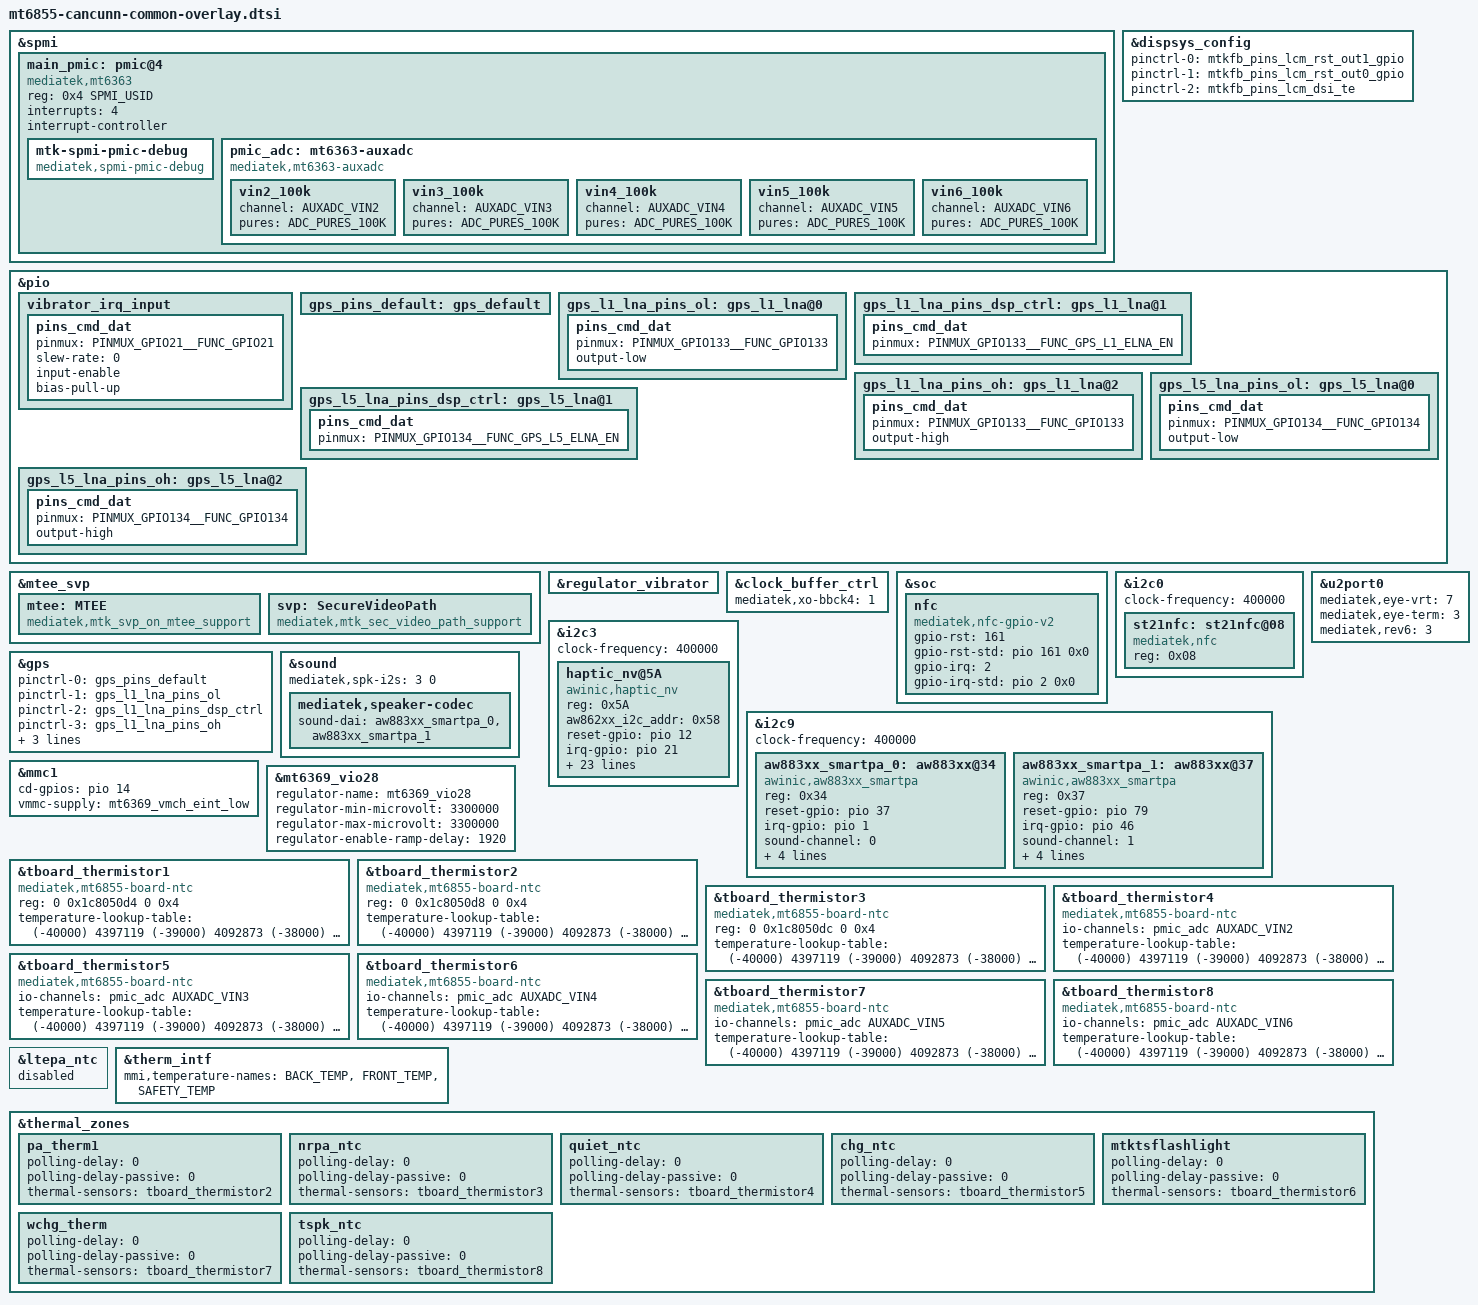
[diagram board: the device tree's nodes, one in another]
/* Copyright (c) 2020, The Linux Foundation. All rights reserved.
 *
 * This program is free software; you can redistribute it and/or modify
 * it under the terms of the GNU General Public License version 2 and
 * only version 2 as published by the Free Software Foundation.
 *
 * This program is distributed in the hope that it will be useful,
 * but WITHOUT ANY WARRANTY; without even the implied warranty of
 * MERCHANTABILITY or FITNESS FOR A PARTICULAR PURPOSE.  See the
 * GNU General Public License for more details.
 */

#include "mediatek/mt6855-moto-common-overlay.dtsi"
#include <dt-bindings/gpio/gpio.h>
#include "mediatek/cancunn-display.dtsi"
#include "mediatek/cancunn-charger.dtsi"
#include "mediatek/mt6855_cancunn_camera_overlay.dtsi"
#include "mediatek/cancunn-fps.dtsi"
#include "mediatek/cancunn-sar.dtsi"
#include "mediatek/mt6855-moto-memory.dtsi"

//#include "mediatek/mt6363.dtsi"
#include <dt-bindings/iio/mt635x-auxadc.h>
#include <dt-bindings/spmi/spmi.h>

&spmi {
	main_pmic: pmic@4 {
		compatible = "mediatek,mt6363";
		reg = <0x4 SPMI_USID>;
		interrupts = <4>;
		#address-cells = <1>;
		#size-cells = <0>;
		interrupt-controller;
		#interrupt-cells = <2>;

		mtk-spmi-pmic-debug {
			compatible = "mediatek,spmi-pmic-debug";
		};

		pmic_adc: mt6363-auxadc {
			compatible = "mediatek,mt6363-auxadc";
			#io-channel-cells = <1>;
			vin2_100k {
				channel = <AUXADC_VIN2>;
				pures = <ADC_PURES_100K>;
			};
			vin3_100k {
				channel = <AUXADC_VIN3>;
				pures = <ADC_PURES_100K>;
			};
			vin4_100k {
				channel = <AUXADC_VIN4>;
				pures = <ADC_PURES_100K>;
			};
			vin5_100k {
				channel = <AUXADC_VIN5>;
				pures = <ADC_PURES_100K>;
			};
                        vin6_100k {
				channel = <AUXADC_VIN6>;
				pures = <ADC_PURES_100K>;
			};
		};

	};
};

&dispsys_config {
	pinctrl-names =
		"lcm_rst_out1_gpio", "lcm_rst_out0_gpio",
		"mode_te_te";
	pinctrl-0 = <&mtkfb_pins_lcm_rst_out1_gpio>;
	pinctrl-1 = <&mtkfb_pins_lcm_rst_out0_gpio>;
	pinctrl-2 = <&mtkfb_pins_lcm_dsi_te>;
	status = "okay";
};

&pio {
	vibrator_irq_input: vibrator_irq_input {
		pins_cmd_dat {
			pinmux = <PINMUX_GPIO21__FUNC_GPIO21>;
			slew-rate = <0>;
			input-enable;
			bias-pull-up;
		};
	};

/*
	fingerfp_rst_high: fingerfp_rst_high {
		pins_cmd_dat {
			pinmux = <PINMUX_GPIO157__FUNC_GPIO157>;
			slew-rate = <1>;
			output-high;
		};
	};

	fingerfp_rst_low: fingerfp_rst_low {
		pins_cmd_dat {
			pinmux = <PINMUX_GPIO157__FUNC_GPIO157>;
			slew-rate = <1>;
			output-low;
		};
	};

	fingerfp_irq_active: fingerfp_irq_active {
		pins_cmd_dat {
			pinmux = <PINMUX_GPIO15__FUNC_GPIO15>;
			slew-rate = <0>;
			bias-disable;
		};
	};

	fingerfp_spi_active: fingerfp_spi_active {
		pins_cmd_dat {
			pinmux = <PINMUX_GPIO68__FUNC_SPI1_MI>, <PINMUX_GPIO66__FUNC_SPI1_CSB>, <PINMUX_GPIO67__FUNC_SPI1_MO>, <PINMUX_GPIO65__FUNC_SPI1_CLK>;
			drive-strength = <2>;
		};
	};

	fingerfp_spi_default: fingerfp_spi_default {
		pins_cmd_dat {
			pinmux = <PINMUX_GPIO68__FUNC_SPI1_MI>, <PINMUX_GPIO66__FUNC_SPI1_CSB>, <PINMUX_GPIO67__FUNC_SPI1_MO>, <PINMUX_GPIO65__FUNC_SPI1_CLK>;
			drive-strength = <2>;
		};
	};
	fps_irq: fps_irq {
		pins_cmd_dat {
			pinmux = <PINMUX_GPIO15__FUNC_GPIO15>;
			slew-rate = <0>;
			bias-disable;
		};
	};

	fps_reset_high: fps_reset_high {
		pins_cmd_dat {
			pinmux = <PINMUX_GPIO157__FUNC_GPIO157>;
			slew-rate = <1>;
			output-high;
		};
	};

	fps_reset_low: fps_reset_low {
		pins_cmd_dat {
			pinmux = <PINMUX_GPIO157__FUNC_GPIO157>;
			slew-rate = <1>;
			output-low;
		};
	};
*/
};

/* FINGERPRINT start */


/* SVP */
&mtee_svp {
	mtee: MTEE {
		compatible = "mediatek,mtk_svp_on_mtee_support";
	};
	svp: SecureVideoPath {
		compatible = "mediatek,mtk_sec_video_path_support";
	};
};

/*
&spi1 {
	status = "okay";
	mediatek,pad-select = <0>, <1>;
	tee-only;

	fingerprint@0 {
		compatible = "mediatek,fingerprint";
		reg = <0>;
		spi-max-frequency = <8000000>;
		status = "okay";
	};
	fpc_tee@1 {
		compatible = "fpc,fpc_spi";
		reg = <1>;
		fpc,enable-wakeup;
		spi-max-frequency = <8000000>;
		netlink-event = <31>;
		status = "okay";
	};
};

&odm {
	fp_egistec {
		compatible = "fp-egistec";
		interrupt-parent = <&pio>;
		interrupts = <15 IRQ_TYPE_EDGE_RISING 15 0>;

		egistec,gpio_reset = <&pio 157 0x0>;
		egistec,gpio_irq = <&pio 15 0x0>;
		fp-ctrl-power;
		vcc_fp-supply = <&mt6369_vfp>;	// ldo for support module vcc
		egis-fp,vcc-voltage = <3300000 3300000>;	// ldo voltage default 3.3V
		egis-fp,vcc-current = <100000>;
		pinctrl-names = "egis_rst_high", "egis_rst_low", "egis_irq_active", "egis_spi_active", "egis_spi_default";
		pinctrl-0 = <&fingerfp_rst_high>;
		pinctrl-1 = <&fingerfp_rst_low>;
		pinctrl-2 = <&fingerfp_irq_active>;
		pinctrl-3 = <&fingerfp_spi_active>;
		pinctrl-4 = <&fingerfp_spi_default>;

		status="okay";
	};

	fingerprint_int: fingerprint_int {
		compatible = "mediatek,fingerprint-fpc";
		fpc,enable-wakeup;
		interrupt-parent = <&pio>;
		interrupts = <15 IRQ_TYPE_EDGE_RISING 15 0>;
		rgltr-ctrl-support;
		fp,vdd-supply = <&mt6369_vfp>;
		fp,voltage-range = <3300000 3300000>;
		fp,vdd-current = <100000>;
		pinctrl-names = "fingerprint_irq", "fingerprint_reset_high", "fingerprint_reset_low";
		pinctrl-0 = <&fps_irq>;
		pinctrl-1 = <&fps_reset_high>;
		pinctrl-2 = <&fps_reset_low>;
		fpc,rst= <&pio 157 0>;
		fpc,irq = <&pio 15 0>;
		status = "okay";
	};
};
*/

&regulator_vibrator {
	status = "ok";
};


&clock_buffer_ctrl {
	mediatek,xo-bbck4 = <1>;
};

&soc {
      nfc {
        compatible = "mediatek,nfc-gpio-v2";
        gpio-rst = <161>;
        gpio-rst-std = <&pio 161 0x0>;
        gpio-irq = <2>;
        gpio-irq-std = <&pio 2 0x0>;
        status = "okay";
      };
};


&i2c0 {
        status = "okay";
        clock-frequency = <400000>;
	st21nfc: st21nfc@08 {
		compatible = "mediatek,nfc";
		reg = <0x08>;
		//interrupt-parent = <&pio>;
		//interrupts = <2 0>;
		//reset-gpio = <&pio 161 0x00>;
		//irq-gpio = <&pio 2 0x00>;
		//clkreq-gpios = <&pio 160 0x00>;
		status = "ok";
	};
};

&i2c3 {
	clock-frequency = <400000>;
	haptic_nv@5A{
		compatible = "awinic,haptic_nv";
		reg = < 0x5A >;
		aw862xx_i2c_addr = < 0x58 >;
		reset-gpio = <&pio 12 0>;
		irq-gpio = <&pio 21 0>;
		pinctrl-names = "irq_active";
		pinctrl-0 = <&vibrator_irq_input>;
		aw8622x_vib_lk_f0_cali = < 0 >;
		aw8622x_vib_mode = < 0 >; /* mode: RAM mode->0; CONT mode->1 */
		aw8622x_vib_f0_pre = < 2050 >;
		aw8622x_vib_f0_cali_percen = < 7 >;
		aw8622x_vib_cont_drv1_lvl = < 0x7F >;
		aw8622x_vib_cont_drv2_lvl = < 0x38 >;
		aw8622x_vib_cont_brk_time = < 0x08 >;
		aw8622x_vib_cont_tset = < 0x06 >;
		aw8622x_vib_cont_bemf_set = < 0x02 >;
		aw8622x_vib_cont_drv_width = < 0x56 >;
		aw8622x_vib_cont_wait_num = < 0x06 >;
		aw8622x_vib_cont_brk_gain = < 0x0A >;
		aw8622x_vib_cont_drv1_time = < 0x08 >;
		aw8622x_vib_cont_drv2_time = < 0x14 >;
		aw8622x_vib_cont_track_margin = < 0x0F >;
		aw8622x_vib_sine_array = < 0x05 0xB2 0xFF 0xEF >; /* SIN_H SIN_L COS_H COS_L*/
		aw8622x_vib_d2s_gain = < 0x05 >;
		aw8622x_vib_prctmode = < 0x2D 0x3E 0x3F >;
		aw8622x_vib_trig_config = < 0 0 0 1 0 2 0
					0 0 0 1 0 2 0
					0 0 0 1 0 2 0 >;
		aw8622x_vib_duration_time = < 34 67 100 >;
		aw8622x_vib_is_enabled_auto_brk;
		status = "okay";
	};
};

/* GPS GPIO standardization start */
&pio {
	gps_pins_default: gps_default {
	};
	gps_l1_lna_pins_ol: gps_l1_lna@0 {
		pins_cmd_dat {
			pinmux = <PINMUX_GPIO133__FUNC_GPIO133>;
			output-low;
		};
	};
	gps_l1_lna_pins_dsp_ctrl: gps_l1_lna@1 {
		pins_cmd_dat {
			pinmux = <PINMUX_GPIO133__FUNC_GPS_L1_ELNA_EN>;
		};
	};
	gps_l1_lna_pins_oh: gps_l1_lna@2 {
		pins_cmd_dat {
			pinmux = <PINMUX_GPIO133__FUNC_GPIO133>;
			output-high;
		};
	};
	gps_l5_lna_pins_ol: gps_l5_lna@0 {
		pins_cmd_dat {
			pinmux = <PINMUX_GPIO134__FUNC_GPIO134>;
			output-low;
		};
	};
	gps_l5_lna_pins_dsp_ctrl: gps_l5_lna@1 {
		pins_cmd_dat {
			pinmux = <PINMUX_GPIO134__FUNC_GPS_L5_ELNA_EN>;
		};
	};
	gps_l5_lna_pins_oh: gps_l5_lna@2 {
		pins_cmd_dat {
			pinmux = <PINMUX_GPIO134__FUNC_GPIO134>;
			output-high;
		};
	};
};



&gps {
	pinctrl-names = "default",
		"gps_l1_lna_disable",
		"gps_l1_lna_dsp_ctrl",
		"gps_l1_lna_enable",
		"gps_l5_lna_disable",
		"gps_l5_lna_dsp_ctrl",
		"gps_l5_lna_enable";
	pinctrl-0 = <&gps_pins_default>;
	pinctrl-1 = <&gps_l1_lna_pins_ol>;
	pinctrl-2 = <&gps_l1_lna_pins_dsp_ctrl>;
	pinctrl-3 = <&gps_l1_lna_pins_oh>;
	pinctrl-4 = <&gps_l5_lna_pins_ol>;
	pinctrl-5 = <&gps_l5_lna_pins_dsp_ctrl>;
	pinctrl-6 = <&gps_l5_lna_pins_oh>;
	status = "okay";
};
/* GPS GPIO standardization end */

//#include "mediatek/cust_mt6855_touch_1080x2400.dtsi"
#include "mediatek/cust_mt6855_camera_v4l2.dtsi"
/delete-node/ &camera_main_two_af_mtk;

&i2c9 {
	status = "okay";
	clock-frequency = <400000>;
	#address-cells = <1>;
	#size-cells = <0>;

	aw883xx_smartpa_0: aw883xx@34 {
                compatible = "awinic,aw883xx_smartpa";
                #sound-dai-cells = <0>;
                reg = <0x34>;
                reset-gpio = <&pio 37 0>;
                irq-gpio = <&pio 1 0>;
                sound-channel = <0>;
                re-min = <1000>;
                re-max = <40000>;
		rename-flag=<1>;
		fade-enable = <1>;
                status = "okay";
        };
        aw883xx_smartpa_1: aw883xx@37 {
                compatible = "awinic,aw883xx_smartpa";
                #sound-dai-cells = <0>;
                reg = <0x37>;
                reset-gpio = <&pio 79 0>;
                irq-gpio = <&pio 46 0>;
                sound-channel = <1>;
                re-min = <1000>;
                re-max = <40000>;
		rename-flag=<1>;
		fade-enable = <1>;
                status = "okay";
        };
};

&sound {
	mediatek,spk-i2s = <3 0>;
	mediatek,speaker-codec {
		sound-dai = <&aw883xx_smartpa_0 &aw883xx_smartpa_1>;
	};
};

&mmc1 {
	cd-gpios = <&pio 14 GPIO_ACTIVE_HIGH>;
	vmmc-supply = <&mt6369_vmch_eint_low>;
};
#include "cancunn-touch.dtsi"

//for alsps sensor tmd2755x
&mt6369_vio28 {
	regulator-name = "mt6369_vio28";
	regulator-min-microvolt = <3300000>;
	regulator-max-microvolt = <3300000>;
	regulator-enable-ramp-delay = <1920>;
};

&u2port0{
	mediatek,eye-vrt = <7>;
	mediatek,eye-term = <3>;
	mediatek,rev6 = <3>;
};


//#include <k6855v1_64/cust.dtsi>
/*End of this file, DO NOT ADD ANYTHING HERE*/

&tboard_thermistor1 {
	compatible = "mediatek,mt6855-board-ntc";
	status = "okay";
	#thermal-sensor-cells = <0>;
	reg = <0 0x1c8050d4 0 0x4>; /* TIA DATA T0 */
	temperature-lookup-table = <
		(-40000) 4397119
		(-39000) 4092873
		(-38000) 3811717
		(-37000) 3551748
		(-36000) 3311235
		(-35000) 3088598
		(-34000) 2882395
		(-33000) 2691309
		(-32000) 2514137
		(-31000) 2349777
		(-30000) 2197225
		(-29000) 2055557
		(-28000) 1923931
		(-27000) 1801573
		(-26000) 1687773
		(-25000) 1581880
		(-24000) 1483099
		(-23000) 1391113
		(-22000) 1305412
		(-21000) 1225530
		(-20000) 1151036
		(-19000) 1081535
		(-18000) 1016661
		(-17000) 956079
		(-16000) 899480
		(-15000) 846578
		(-14000) 797111
		(-13000) 750834
		(-12000) 707523
		(-11000) 666972
		(-10000) 628988
		(-9000) 593342
		(-8000) 559930
		(-7000) 528601
		(-6000) 499212
		(-5000) 471632
		(-4000) 445771
		(-3000) 421479
		(-2000) 398652
		(-1000) 377192
		0 357011
		1000 338005
		2000 320121
		3000 303286
		4000 287433
		5000 272499
		6000 258426
		7000 245160
		8000 232649
		9000 220847
		10000 209710
		11000 199196
		12000 189268
		13000 179890
		14000 171027
		15000 162651
		16000 154726
		17000 147232
		18000 140142
		19000 133432
		20000 127080
		21000 121066
		22000 115368
		23000 109970
		24000 104852
		25000 100000
		26000 95398
		27000 91032
		28000 86889
		29000 82956
		30000 79222
		31000 75675
		32000 72306
		33000 69104
		34000 66061
		35000 63167
		36000 60415
		37000 57797
		38000 55306
		39000 52934
		40000 50677
		41000 48528
		42000 46482
		43000 44533
		44000 42675
		45000 40904
		46000 39213
		47000 37601
		48000 36063
		49000 34595
		50000 33195
		51000 31859
		52000 30584
		53000 29366
		54000 28203
		55000 27091
		56000 26028
		57000 25013
		58000 24042
		59000 23113
		60000 22224
		61000 21374
		62000 20560
		63000 19782
		64000 19036
		65000 18322
		66000 17640
		67000 16986
		68000 16360
		69000 15759
		70000 15184
		71000 14631
		72000 14100
		73000 13591
		74000 13103
		75000 12635
		76000 12187
		77000 11756
		78000 11343
		79000 10946
		80000 10565
		81000 10199
		82000 9847
		83000 9509
		84000 9184
		85000 8872
		86000 8572
		87000 8283
		88000 8005
		89000 7738
		90000 7481
		91000 7234
		92000 6997
		93000 6769
		94000 6548
		95000 6337
		96000 6132
		97000 5934
		98000 5744
		99000 5561
		100000 5384
		101000 5214
		102000 5051
		103000 4893
		104000 4741
		105000 4594
		106000 4453
		107000 4316
		108000 4184
		109000 4057
		110000 3934
		111000 3816
		112000 3701
		113000 3591
		114000 3484
		115000 3380
		116000 3281
		117000 3185
		118000 3093
		119000 3003
		120000 2916
		121000 2832
		122000 2751
		123000 2672
		124000 2596
		125000 2522>;
};

&tboard_thermistor2 {
	compatible = "mediatek,mt6855-board-ntc";
	status = "okay";
	#thermal-sensor-cells = <0>;
	reg = <0 0x1c8050d8 0 0x4>; /* TIA DATA T1 */
	temperature-lookup-table = <
		(-40000) 4397119
		(-39000) 4092873
		(-38000) 3811717
		(-37000) 3551748
		(-36000) 3311235
		(-35000) 3088598
		(-34000) 2882395
		(-33000) 2691309
		(-32000) 2514137
		(-31000) 2349777
		(-30000) 2197225
		(-29000) 2055557
		(-28000) 1923931
		(-27000) 1801573
		(-26000) 1687773
		(-25000) 1581880
		(-24000) 1483099
		(-23000) 1391113
		(-22000) 1305412
		(-21000) 1225530
		(-20000) 1151036
		(-19000) 1081535
		(-18000) 1016661
		(-17000) 956079
		(-16000) 899480
		(-15000) 846578
		(-14000) 797111
		(-13000) 750834
		(-12000) 707523
		(-11000) 666972
		(-10000) 628988
		(-9000) 593342
		(-8000) 559930
		(-7000) 528601
		(-6000) 499212
		(-5000) 471632
		(-4000) 445771
		(-3000) 421479
		(-2000) 398652
		(-1000) 377192
		0 357011
		1000 338005
		2000 320121
		3000 303286
		4000 287433
		5000 272499
		6000 258426
		7000 245160
		8000 232649
		9000 220847
		10000 209710
		11000 199196
		12000 189268
		13000 179890
		14000 171027
		15000 162651
		16000 154726
		17000 147232
		18000 140142
		19000 133432
		20000 127080
		21000 121066
		22000 115368
		23000 109970
		24000 104852
		25000 100000
		26000 95398
		27000 91032
		28000 86889
		29000 82956
		30000 79222
		31000 75675
		32000 72306
		33000 69104
		34000 66061
		35000 63167
		36000 60415
		37000 57797
		38000 55306
		39000 52934
		40000 50677
		41000 48528
		42000 46482
		43000 44533
		44000 42675
		45000 40904
		46000 39213
		47000 37601
		48000 36063
		49000 34595
		50000 33195
		51000 31859
		52000 30584
		53000 29366
		54000 28203
		55000 27091
		56000 26028
		57000 25013
		58000 24042
		59000 23113
		60000 22224
		61000 21374
		62000 20560
		63000 19782
		64000 19036
		65000 18322
		66000 17640
		67000 16986
		68000 16360
		69000 15759
		70000 15184
		71000 14631
		72000 14100
		73000 13591
		74000 13103
		75000 12635
		76000 12187
		77000 11756
		78000 11343
		79000 10946
		80000 10565
		81000 10199
		82000 9847
		83000 9509
		84000 9184
		85000 8872
		86000 8572
		87000 8283
		88000 8005
		89000 7738
		90000 7481
		91000 7234
		92000 6997
		93000 6769
		94000 6548
		95000 6337
		96000 6132
		97000 5934
		98000 5744
		99000 5561
		100000 5384
		101000 5214
		102000 5051
		103000 4893
		104000 4741
		105000 4594
		106000 4453
		107000 4316
		108000 4184
		109000 4057
		110000 3934
		111000 3816
		112000 3701
		113000 3591
		114000 3484
		115000 3380
		116000 3281
		117000 3185
		118000 3093
		119000 3003
		120000 2916
		121000 2832
		122000 2751
		123000 2672
		124000 2596
		125000 2522>;
};

&tboard_thermistor3 {
	compatible = "mediatek,mt6855-board-ntc";
	status = "okay";
	#thermal-sensor-cells = <0>;
	reg = <0 0x1c8050dc 0 0x4>; /* TIA DATA T2 */
	temperature-lookup-table = <
		(-40000) 4397119
		(-39000) 4092873
		(-38000) 3811717
		(-37000) 3551748
		(-36000) 3311235
		(-35000) 3088598
		(-34000) 2882395
		(-33000) 2691309
		(-32000) 2514137
		(-31000) 2349777
		(-30000) 2197225
		(-29000) 2055557
		(-28000) 1923931
		(-27000) 1801573
		(-26000) 1687773
		(-25000) 1581880
		(-24000) 1483099
		(-23000) 1391113
		(-22000) 1305412
		(-21000) 1225530
		(-20000) 1151036
		(-19000) 1081535
		(-18000) 1016661
		(-17000) 956079
		(-16000) 899480
		(-15000) 846578
		(-14000) 797111
		(-13000) 750834
		(-12000) 707523
		(-11000) 666972
		(-10000) 628988
		(-9000) 593342
		(-8000) 559930
		(-7000) 528601
		(-6000) 499212
		(-5000) 471632
		(-4000) 445771
		(-3000) 421479
		(-2000) 398652
		(-1000) 377192
		0 357011
		1000 338005
		2000 320121
		3000 303286
		4000 287433
		5000 272499
		6000 258426
		7000 245160
		8000 232649
		9000 220847
		10000 209710
		11000 199196
		12000 189268
		13000 179890
		14000 171027
		15000 162651
		16000 154726
		17000 147232
		18000 140142
		19000 133432
		20000 127080
		21000 121066
		22000 115368
		23000 109970
		24000 104852
		25000 100000
		26000 95398
		27000 91032
		28000 86889
		29000 82956
		30000 79222
		31000 75675
		32000 72306
		33000 69104
		34000 66061
		35000 63167
		36000 60415
		37000 57797
		38000 55306
		39000 52934
		40000 50677
		41000 48528
		42000 46482
		43000 44533
		44000 42675
		45000 40904
		46000 39213
		47000 37601
		48000 36063
		49000 34595
		50000 33195
		51000 31859
		52000 30584
		53000 29366
		54000 28203
		55000 27091
		56000 26028
		57000 25013
		58000 24042
		59000 23113
		60000 22224
		61000 21374
		62000 20560
		63000 19782
		64000 19036
		65000 18322
		66000 17640
		67000 16986
		68000 16360
		69000 15759
		70000 15184
		71000 14631
		72000 14100
		73000 13591
		74000 13103
		75000 12635
		76000 12187
		77000 11756
		78000 11343
		79000 10946
		80000 10565
		81000 10199
		82000 9847
		83000 9509
		84000 9184
		85000 8872
		86000 8572
		87000 8283
		88000 8005
		89000 7738
		90000 7481
		91000 7234
		92000 6997
		93000 6769
		94000 6548
		95000 6337
		96000 6132
		97000 5934
		98000 5744
		99000 5561
		100000 5384
		101000 5214
		102000 5051
		103000 4893
		104000 4741
		105000 4594
		106000 4453
		107000 4316
		108000 4184
		109000 4057
		110000 3934
		111000 3816
		112000 3701
		113000 3591
		114000 3484
		115000 3380
		116000 3281
		117000 3185
		118000 3093
		119000 3003
		120000 2916
		121000 2832
		122000 2751
		123000 2672
		124000 2596
		125000 2522>;
};

&tboard_thermistor4 {
	compatible = "mediatek,mt6855-board-ntc";
	status = "okay";
	#thermal-sensor-cells = <0>;
	io-channels = <&pmic_adc AUXADC_VIN2>;
	io-channel-names = "QUIET_NTC";
	temperature-lookup-table = <
		(-40000) 4397119
		(-39000) 4092873
		(-38000) 3811717
		(-37000) 3551748
		(-36000) 3311235
		(-35000) 3088598
		(-34000) 2882395
		(-33000) 2691309
		(-32000) 2514137
		(-31000) 2349777
		(-30000) 2197225
		(-29000) 2055557
		(-28000) 1923931
		(-27000) 1801573
		(-26000) 1687773
		(-25000) 1581880
		(-24000) 1483099
		(-23000) 1391113
		(-22000) 1305412
		(-21000) 1225530
		(-20000) 1151036
		(-19000) 1081535
		(-18000) 1016661
		(-17000) 956079
		(-16000) 899480
		(-15000) 846578
		(-14000) 797111
		(-13000) 750834
		(-12000) 707523
		(-11000) 666972
		(-10000) 628988
		(-9000) 593342
		(-8000) 559930
		(-7000) 528601
		(-6000) 499212
		(-5000) 471632
		(-4000) 445771
		(-3000) 421479
		(-2000) 398652
		(-1000) 377192
		0 357011
		1000 338005
		2000 320121
		3000 303286
		4000 287433
		5000 272499
		6000 258426
		7000 245160
		8000 232649
		9000 220847
		10000 209710
		11000 199196
		12000 189268
		13000 179890
		14000 171027
		15000 162651
		16000 154726
		17000 147232
		18000 140142
		19000 133432
		20000 127080
		21000 121066
		22000 115368
		23000 109970
		24000 104852
		25000 100000
		26000 95398
		27000 91032
		28000 86889
		29000 82956
		30000 79222
		31000 75675
		32000 72306
		33000 69104
		34000 66061
		35000 63167
		36000 60415
		37000 57797
		38000 55306
		39000 52934
		40000 50677
		41000 48528
		42000 46482
		43000 44533
		44000 42675
		45000 40904
		46000 39213
		47000 37601
		48000 36063
		49000 34595
		50000 33195
		51000 31859
		52000 30584
		53000 29366
		54000 28203
		55000 27091
		56000 26028
		57000 25013
		58000 24042
		59000 23113
		60000 22224
		61000 21374
		62000 20560
		63000 19782
		64000 19036
		65000 18322
		66000 17640
		67000 16986
		68000 16360
		69000 15759
		70000 15184
		71000 14631
		72000 14100
		73000 13591
		74000 13103
		75000 12635
		76000 12187
		77000 11756
		78000 11343
		79000 10946
		80000 10565
		81000 10199
		82000 9847
		83000 9509
		84000 9184
		85000 8872
		86000 8572
		87000 8283
		88000 8005
		89000 7738
		90000 7481
		91000 7234
		92000 6997
		93000 6769
		94000 6548
		95000 6337
		96000 6132
		97000 5934
		98000 5744
		99000 5561
		100000 5384
		101000 5214
		102000 5051
		103000 4893
		104000 4741
		105000 4594
		106000 4453
		107000 4316
		108000 4184
		109000 4057
		110000 3934
		111000 3816
		112000 3701
		113000 3591
		114000 3484
		115000 3380
		116000 3281
		117000 3185
		118000 3093
		119000 3003
		120000 2916
		121000 2832
		122000 2751
		123000 2672
		124000 2596
		125000 2522>;
};

&tboard_thermistor5 {
	compatible = "mediatek,mt6855-board-ntc";
	status = "okay";
	#thermal-sensor-cells = <0>;
	io-channels = <&pmic_adc AUXADC_VIN3>;
	io-channel-names = "Charger_NTC";
	temperature-lookup-table = <
		(-40000) 4397119
		(-39000) 4092873
		(-38000) 3811717
		(-37000) 3551748
		(-36000) 3311235
		(-35000) 3088598
		(-34000) 2882395
		(-33000) 2691309
		(-32000) 2514137
		(-31000) 2349777
		(-30000) 2197225
		(-29000) 2055557
		(-28000) 1923931
		(-27000) 1801573
		(-26000) 1687773
		(-25000) 1581880
		(-24000) 1483099
		(-23000) 1391113
		(-22000) 1305412
		(-21000) 1225530
		(-20000) 1151036
		(-19000) 1081535
		(-18000) 1016661
		(-17000) 956079
		(-16000) 899480
		(-15000) 846578
		(-14000) 797111
		(-13000) 750834
		(-12000) 707523
		(-11000) 666972
		(-10000) 628988
		(-9000) 593342
		(-8000) 559930
		(-7000) 528601
		(-6000) 499212
		(-5000) 471632
		(-4000) 445771
		(-3000) 421479
		(-2000) 398652
		(-1000) 377192
		0 357011
		1000 338005
		2000 320121
		3000 303286
		4000 287433
		5000 272499
		6000 258426
		7000 245160
		8000 232649
		9000 220847
		10000 209710
		11000 199196
		12000 189268
		13000 179890
		14000 171027
		15000 162651
		16000 154726
		17000 147232
		18000 140142
		19000 133432
		20000 127080
		21000 121066
		22000 115368
		23000 109970
		24000 104852
		25000 100000
		26000 95398
		27000 91032
		28000 86889
		29000 82956
		30000 79222
		31000 75675
		32000 72306
		33000 69104
		34000 66061
		35000 63167
		36000 60415
		37000 57797
		38000 55306
		39000 52934
		40000 50677
		41000 48528
		42000 46482
		43000 44533
		44000 42675
		45000 40904
		46000 39213
		47000 37601
		48000 36063
		49000 34595
		50000 33195
		51000 31859
		52000 30584
		53000 29366
		54000 28203
		55000 27091
		56000 26028
		57000 25013
		58000 24042
		59000 23113
		60000 22224
		61000 21374
		62000 20560
		63000 19782
		64000 19036
		65000 18322
		66000 17640
		67000 16986
		68000 16360
		69000 15759
		70000 15184
		71000 14631
		72000 14100
		73000 13591
		74000 13103
		75000 12635
		76000 12187
		77000 11756
		78000 11343
		79000 10946
		80000 10565
		81000 10199
		82000 9847
		83000 9509
		84000 9184
		85000 8872
		86000 8572
		87000 8283
		88000 8005
		89000 7738
		90000 7481
		91000 7234
		92000 6997
		93000 6769
		94000 6548
		95000 6337
		96000 6132
		97000 5934
		98000 5744
		99000 5561
		100000 5384
		101000 5214
		102000 5051
		103000 4893
		104000 4741
		105000 4594
		106000 4453
		107000 4316
		108000 4184
		109000 4057
		110000 3934
		111000 3816
		112000 3701
		113000 3591
		114000 3484
		115000 3380
		116000 3281
		117000 3185
		118000 3093
		119000 3003
		120000 2916
		121000 2832
		122000 2751
		123000 2672
		124000 2596
		125000 2522>;
};

&tboard_thermistor6 {
	compatible = "mediatek,mt6855-board-ntc";
	status = "okay";
	#thermal-sensor-cells = <0>;
	io-channels = <&pmic_adc AUXADC_VIN4>;
	io-channel-names = "Flash_LED_NTC";
	temperature-lookup-table = <
		(-40000) 4397119
		(-39000) 4092873
		(-38000) 3811717
		(-37000) 3551748
		(-36000) 3311235
		(-35000) 3088598
		(-34000) 2882395
		(-33000) 2691309
		(-32000) 2514137
		(-31000) 2349777
		(-30000) 2197225
		(-29000) 2055557
		(-28000) 1923931
		(-27000) 1801573
		(-26000) 1687773
		(-25000) 1581880
		(-24000) 1483099
		(-23000) 1391113
		(-22000) 1305412
		(-21000) 1225530
		(-20000) 1151036
		(-19000) 1081535
		(-18000) 1016661
		(-17000) 956079
		(-16000) 899480
		(-15000) 846578
		(-14000) 797111
		(-13000) 750834
		(-12000) 707523
		(-11000) 666972
		(-10000) 628988
		(-9000) 593342
		(-8000) 559930
		(-7000) 528601
		(-6000) 499212
		(-5000) 471632
		(-4000) 445771
		(-3000) 421479
		(-2000) 398652
		(-1000) 377192
		0 357011
		1000 338005
		2000 320121
		3000 303286
		4000 287433
		5000 272499
		6000 258426
		7000 245160
		8000 232649
		9000 220847
		10000 209710
		11000 199196
		12000 189268
		13000 179890
		14000 171027
		15000 162651
		16000 154726
		17000 147232
		18000 140142
		19000 133432
		20000 127080
		21000 121066
		22000 115368
		23000 109970
		24000 104852
		25000 100000
		26000 95398
		27000 91032
		28000 86889
		29000 82956
		30000 79222
		31000 75675
		32000 72306
		33000 69104
		34000 66061
		35000 63167
		36000 60415
		37000 57797
		38000 55306
		39000 52934
		40000 50677
		41000 48528
		42000 46482
		43000 44533
		44000 42675
		45000 40904
		46000 39213
		47000 37601
		48000 36063
		49000 34595
		50000 33195
		51000 31859
		52000 30584
		53000 29366
		54000 28203
		55000 27091
		56000 26028
		57000 25013
		58000 24042
		59000 23113
		60000 22224
		61000 21374
		62000 20560
		63000 19782
		64000 19036
		65000 18322
		66000 17640
		67000 16986
		68000 16360
		69000 15759
		70000 15184
		71000 14631
		72000 14100
		73000 13591
		74000 13103
		75000 12635
		76000 12187
		77000 11756
		78000 11343
		79000 10946
		80000 10565
		81000 10199
		82000 9847
		83000 9509
		84000 9184
		85000 8872
		86000 8572
		87000 8283
		88000 8005
		89000 7738
		90000 7481
		91000 7234
		92000 6997
		93000 6769
		94000 6548
		95000 6337
		96000 6132
		97000 5934
		98000 5744
		99000 5561
		100000 5384
		101000 5214
		102000 5051
		103000 4893
		104000 4741
		105000 4594
		106000 4453
		107000 4316
		108000 4184
		109000 4057
		110000 3934
		111000 3816
		112000 3701
		113000 3591
		114000 3484
		115000 3380
		116000 3281
		117000 3185
		118000 3093
		119000 3003
		120000 2916
		121000 2832
		122000 2751
		123000 2672
		124000 2596
		125000 2522>;
};

&tboard_thermistor7 {
	compatible = "mediatek,mt6855-board-ntc";
	status = "okay";
	#thermal-sensor-cells = <0>;
	io-channels = <&pmic_adc AUXADC_VIN5>;
	io-channel-names = "WLC_NTC";
	temperature-lookup-table = <
		(-40000) 4397119
		(-39000) 4092873
		(-38000) 3811717
		(-37000) 3551748
		(-36000) 3311235
		(-35000) 3088598
		(-34000) 2882395
		(-33000) 2691309
		(-32000) 2514137
		(-31000) 2349777
		(-30000) 2197225
		(-29000) 2055557
		(-28000) 1923931
		(-27000) 1801573
		(-26000) 1687773
		(-25000) 1581880
		(-24000) 1483099
		(-23000) 1391113
		(-22000) 1305412
		(-21000) 1225530
		(-20000) 1151036
		(-19000) 1081535
		(-18000) 1016661
		(-17000) 956079
		(-16000) 899480
		(-15000) 846578
		(-14000) 797111
		(-13000) 750834
		(-12000) 707523
		(-11000) 666972
		(-10000) 628988
		(-9000) 593342
		(-8000) 559930
		(-7000) 528601
		(-6000) 499212
		(-5000) 471632
		(-4000) 445771
		(-3000) 421479
		(-2000) 398652
		(-1000) 377192
		0 357011
		1000 338005
		2000 320121
		3000 303286
		4000 287433
		5000 272499
		6000 258426
		7000 245160
		8000 232649
		9000 220847
		10000 209710
		11000 199196
		12000 189268
		13000 179890
		14000 171027
		15000 162651
		16000 154726
		17000 147232
		18000 140142
		19000 133432
		20000 127080
		21000 121066
		22000 115368
		23000 109970
		24000 104852
		25000 100000
		26000 95398
		27000 91032
		28000 86889
		29000 82956
		30000 79222
		31000 75675
		32000 72306
		33000 69104
		34000 66061
		35000 63167
		36000 60415
		37000 57797
		38000 55306
		39000 52934
		40000 50677
		41000 48528
		42000 46482
		43000 44533
		44000 42675
		45000 40904
		46000 39213
		47000 37601
		48000 36063
		49000 34595
		50000 33195
		51000 31859
		52000 30584
		53000 29366
		54000 28203
		55000 27091
		56000 26028
		57000 25013
		58000 24042
		59000 23113
		60000 22224
		61000 21374
		62000 20560
		63000 19782
		64000 19036
		65000 18322
		66000 17640
		67000 16986
		68000 16360
		69000 15759
		70000 15184
		71000 14631
		72000 14100
		73000 13591
		74000 13103
		75000 12635
		76000 12187
		77000 11756
		78000 11343
		79000 10946
		80000 10565
		81000 10199
		82000 9847
		83000 9509
		84000 9184
		85000 8872
		86000 8572
		87000 8283
		88000 8005
		89000 7738
		90000 7481
		91000 7234
		92000 6997
		93000 6769
		94000 6548
		95000 6337
		96000 6132
		97000 5934
		98000 5744
		99000 5561
		100000 5384
		101000 5214
		102000 5051
		103000 4893
		104000 4741
		105000 4594
		106000 4453
		107000 4316
		108000 4184
		109000 4057
		110000 3934
		111000 3816
		112000 3701
		113000 3591
		114000 3484
		115000 3380
		116000 3281
		117000 3185
		118000 3093
		119000 3003
		120000 2916
		121000 2832
		122000 2751
		123000 2672
		124000 2596
		125000 2522>;
};

&tboard_thermistor8 {
	compatible = "mediatek,mt6855-board-ntc";
	status = "okay";
	#thermal-sensor-cells = <0>;
	io-channels = <&pmic_adc AUXADC_VIN6>;
	io-channel-names = "TSPK_NTC";
	temperature-lookup-table = <
		(-40000) 4397119
		(-39000) 4092873
		(-38000) 3811717
		(-37000) 3551748
		(-36000) 3311235
		(-35000) 3088598
		(-34000) 2882395
		(-33000) 2691309
		(-32000) 2514137
		(-31000) 2349777
		(-30000) 2197225
		(-29000) 2055557
		(-28000) 1923931
		(-27000) 1801573
		(-26000) 1687773
		(-25000) 1581880
		(-24000) 1483099
		(-23000) 1391113
		(-22000) 1305412
		(-21000) 1225530
		(-20000) 1151036
		(-19000) 1081535
		(-18000) 1016661
		(-17000) 956079
		(-16000) 899480
		(-15000) 846578
		(-14000) 797111
		(-13000) 750834
		(-12000) 707523
		(-11000) 666972
		(-10000) 628988
		(-9000) 593342
		(-8000) 559930
		(-7000) 528601
		(-6000) 499212
		(-5000) 471632
		(-4000) 445771
		(-3000) 421479
		(-2000) 398652
		(-1000) 377192
		0 357011
		1000 338005
		2000 320121
		3000 303286
		4000 287433
		5000 272499
		6000 258426
		7000 245160
		8000 232649
		9000 220847
		10000 209710
		11000 199196
		12000 189268
		13000 179890
		14000 171027
		15000 162651
		16000 154726
		17000 147232
		18000 140142
		19000 133432
		20000 127080
		21000 121066
		22000 115368
		23000 109970
		24000 104852
		25000 100000
		26000 95398
		27000 91032
		28000 86889
		29000 82956
		30000 79222
		31000 75675
		32000 72306
		33000 69104
		34000 66061
		35000 63167
		36000 60415
		37000 57797
		38000 55306
		39000 52934
		40000 50677
		41000 48528
		42000 46482
		43000 44533
		44000 42675
		45000 40904
		46000 39213
		47000 37601
		48000 36063
		49000 34595
		50000 33195
		51000 31859
		52000 30584
		53000 29366
		54000 28203
		55000 27091
		56000 26028
		57000 25013
		58000 24042
		59000 23113
		60000 22224
		61000 21374
		62000 20560
		63000 19782
		64000 19036
		65000 18322
		66000 17640
		67000 16986
		68000 16360
		69000 15759
		70000 15184
		71000 14631
		72000 14100
		73000 13591
		74000 13103
		75000 12635
		76000 12187
		77000 11756
		78000 11343
		79000 10946
		80000 10565
		81000 10199
		82000 9847
		83000 9509
		84000 9184
		85000 8872
		86000 8572
		87000 8283
		88000 8005
		89000 7738
		90000 7481
		91000 7234
		92000 6997
		93000 6769
		94000 6548
		95000 6337
		96000 6132
		97000 5934
		98000 5744
		99000 5561
		100000 5384
		101000 5214
		102000 5051
		103000 4893
		104000 4741
		105000 4594
		106000 4453
		107000 4316
		108000 4184
		109000 4057
		110000 3934
		111000 3816
		112000 3701
		113000 3591
		114000 3484
		115000 3380
		116000 3281
		117000 3185
		118000 3093
		119000 3003
		120000 2916
		121000 2832
		122000 2751
		123000 2672
		124000 2596
		125000 2522>;
};

&ltepa_ntc {
	status = "disabled";
};

&therm_intf {
	/*Vsensor name should be CASE DIFFERENT with the name in config file*/
	mmi,temperature-names = "BACK_TEMP", "FRONT_TEMP", "SAFETY_TEMP";/*for "back_temp" "front_temp" in config file*/
};

&thermal_zones{
//		ap_ntc: ap_ntc {
//			polling-delay = <0>; /* milliseconds */
//			polling-delay-passive = <0>; /* milliseconds */
//			thermal-sensors = <&tboard_thermistor1>;
//		};
		pa_therm1: pa_therm1 {
			polling-delay = <0>; /* milliseconds */
			polling-delay-passive = <0>; /* milliseconds */
			thermal-sensors = <&tboard_thermistor2>;
		};
		nrpa_ntc: nrpa_ntc {
			polling-delay = <0>; /* milliseconds */
			polling-delay-passive = <0>; /* milliseconds */
			thermal-sensors = <&tboard_thermistor3>;
		};
//		chg_ntc {
//			polling-delay = <0>; /* milliseconds */
//			polling-delay-passive = <0>; /* milliseconds */
//			thermal-sensors = <&tboard_thermistor4>;
//		};
		quiet_ntc {
			polling-delay = <0>; /* milliseconds */
			polling-delay-passive = <0>; /* milliseconds */
			thermal-sensors = <&tboard_thermistor4>;
		};
		chg_ntc {
			polling-delay = <0>; /* milliseconds */
			polling-delay-passive = <0>; /* milliseconds */
			thermal-sensors = <&tboard_thermistor5>;
		};
		mtktsflashlight {
			polling-delay = <0>; /* milliseconds */
			polling-delay-passive = <0>; /* milliseconds */
			thermal-sensors = <&tboard_thermistor6>;
		};
                wchg_therm {
			polling-delay = <0>; /* milliseconds */
			polling-delay-passive = <0>; /* milliseconds */
			thermal-sensors = <&tboard_thermistor7>;
		};
                tspk_ntc {
			polling-delay = <0>; /* milliseconds */
			polling-delay-passive = <0>; /* milliseconds */
			thermal-sensors = <&tboard_thermistor8>;
		};
};
